# ATmega1284RFR2 register map
Vendor: Atmel; File version: 1.0
CPU: other r0p0, little endian, no MPU, no FPU, 4 interrupt priority bits
Registers are 8-bit, read-write, reset 0x0 unless marked. A register's access mark holds for its fields unless they carry their own. Offsets are from the block's base; [hi:lo] are bit positions; 'fields as' and 'values as' point back to an identical list.

## TC3 — Timer/Counter, 16-bit
Base 0x00800038
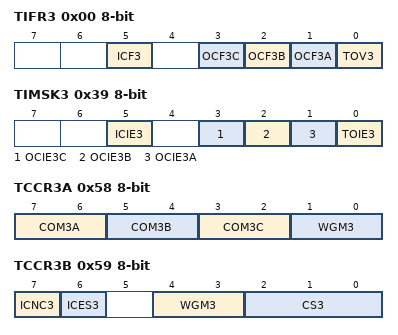
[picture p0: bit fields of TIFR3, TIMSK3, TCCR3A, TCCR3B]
0x00 TIFR3 — Timer/Counter3 Interrupt Flag Register (read-only for debugger)
  [5] ICF3 — Timer/Counter3 Input Capture Flag
  [3] OCF3C — Timer/Counter3 Output Compare C Match Flag
  [2] OCF3B — Timer/Counter3 Output Compare B Match Flag
  [1] OCF3A — Timer/Counter3 Output Compare A Match Flag
  [0] TOV3 — Timer/Counter3 Overflow Flag
0x39 TIMSK3 — Timer/Counter3 Interrupt Mask Register
  [5] ICIE3 — Timer/Counter3 Input Capture Interrupt Enable
  [3] OCIE3C — Timer/Counter3 Output Compare C Match Interrupt Enable
  [2] OCIE3B — Timer/Counter3 Output Compare B Match Interrupt Enable
  [1] OCIE3A — Timer/Counter3 Output Compare A Match Interrupt Enable
  [0] TOIE3 — Timer/Counter3 Overflow Interrupt Enable
0x58 TCCR3A — Timer/Counter3 Control Register A
  [7:6] COM3A — Compare Output Mode for Channel A
    0=NORMAL_PORT_OPERATION_OCNA_OCNB_OCNC_DISCONNECTED; 1=TOGGLE_OCNA_OCNB_OCNC_ON_COMPARE_MATCH; 2=CLEAR_OCNA_OCNB_OCNC_ON_COMPARE_MATCH_SET_OUTPUT_TO_LOW_LEVEL; 3=SET_OCNA_OCNB_OCNC_ON_COMPARE_MATCH_SET_OUTPUT_TO_HIGH_LEVEL
  [5:4] COM3B — Compare Output Mode for Channel B
    values as COM3A
  [3:2] COM3C — Compare Output Mode for Channel C
    values as COM3A
  [1:0] WGM3 — Waveform Generation Mode
    0=NORMAL_MODE_OF_OPERATION; 1=PWM_PHASE_CORRECT_8_BIT; 2=PWM_PHASE_CORRECT_9_BIT; 3=PWM_PHASE_CORRECT_10_BIT
0x59 TCCR3B — Timer/Counter3 Control Register B
  [7] ICNC3 — Input Capture 3 Noise Canceller
  [6] ICES3 — Input Capture 3 Edge Select
  [4:3] WGM3 — Waveform Generation Mode
    values as TCCR3A.WGM3
  [2:0] CS3 — Clock Select
    0=NO_CLOCK_SOURCE_TIMER_COUNTER_STOPPED; 1=CLK_IO_1_NO_PRESCALING; 2=CLK_IO_8_FROM_PRESCALER; 3=CLK_IO_64_FROM_PRESCALER; 4=CLK_IO_256_FROM_PRESCALER; 5=CLK_IO_1024_FROM_PRESCALER; 6=EXTERNAL_CLOCK_SOURCE_ON_TN_PIN_CLOCK_ON_FALLING_EDGE; 7=EXTERNAL_CLOCK_SOURCE_ON_TN_PIN_CLOCK_ON_RISING_EDGE
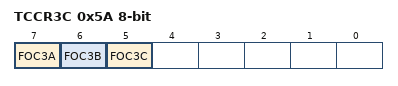
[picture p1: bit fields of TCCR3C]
0x5A TCCR3C — Timer/Counter3 Control Register C
  [7] FOC3A — Force Output Compare for Channel A
  [6] FOC3B — Force Output Compare for Channel B
  [5] FOC3C — Force Output Compare for Channel C
0x5C TCNT3 16-bit (reset mask 0xFF) — Timer/Counter3 Bytes
0x5E ICR3 16-bit (reset mask 0xFF) — Timer/Counter3 Input Capture Register Bytes
0x60 OCR3A 16-bit (reset mask 0xFF) — Timer/Counter3 Output Compare Register A Bytes
0x62 OCR3B 16-bit (reset mask 0xFF) — Timer/Counter3 Output Compare Register B Bytes
0x64 OCR3C 16-bit (reset mask 0xFF) — Timer/Counter3 Output Compare Register C Bytes

## TC4 — Timer/Counter, 16-bit
Base 0x00800039
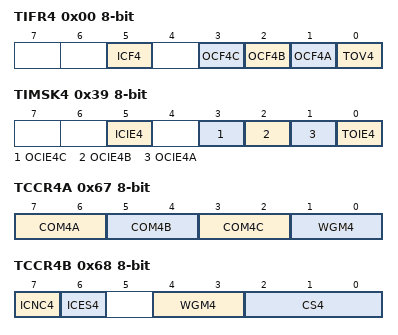
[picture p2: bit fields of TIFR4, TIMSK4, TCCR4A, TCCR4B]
0x00 TIFR4 — Timer/Counter4 Interrupt Flag Register (write-only for debugger)
  [5] ICF4 — Timer/Counter4 Input Capture Flag
  [3] OCF4C — Timer/Counter4 Output Compare C Match Flag
  [2] OCF4B — Timer/Counter4 Output Compare B Match Flag
  [1] OCF4A — Timer/Counter4 Output Compare A Match Flag
  [0] TOV4 — Timer/Counter4 Overflow Flag
0x39 TIMSK4 — Timer/Counter4 Interrupt Mask Register
  [5] ICIE4 — Timer/Counter4 Input Capture Interrupt Enable
  [3] OCIE4C — Timer/Counter4 Output Compare C Match Interrupt Enable
  [2] OCIE4B — Timer/Counter4 Output Compare B Match Interrupt Enable
  [1] OCIE4A — Timer/Counter4 Output Compare A Match Interrupt Enable
  [0] TOIE4 — Timer/Counter4 Overflow Interrupt Enable
0x67 TCCR4A — Timer/Counter4 Control Register A
  [7:6] COM4A — Compare Output Mode for Channel A
    0=NORMAL_OPERATION
  [5:4] COM4B — Compare Output Mode for Channel B
    0=NORMAL_OPERATION
  [3:2] COM4C — Compare Output Mode for Channel C
    0=NORMAL_OPERATION
  [1:0] WGM4 — Waveform Generation Mode
    0=NORMAL_MODE_OF_OPERATION; 1=PWM_PHASE_CORRECT_8_BIT; 2=PWM_PHASE_CORRECT_9_BIT; 3=PWM_PHASE_CORRECT_10_BIT
0x68 TCCR4B — Timer/Counter4 Control Register B
  [7] ICNC4 — Input Capture 4 Noise Canceller
  [6] ICES4 — Input Capture 4 Edge Select
  [4:3] WGM4 — Waveform Generation Mode
    values as TCCR4A.WGM4
  [2:0] CS4 — Clock Select
    0=NO_CLOCK_SOURCE_TIMER_COUNTER_STOPPED; 1=CLK_IO_1_NO_PRESCALING; 2=CLK_IO_8_FROM_PRESCALER; 3=CLK_IO_64_FROM_PRESCALER; 4=CLK_IO_256_FROM_PRESCALER; 5=CLK_IO_1024_FROM_PRESCALER
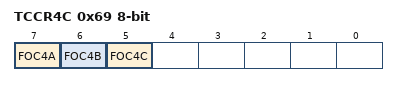
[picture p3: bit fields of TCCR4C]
0x69 TCCR4C — Timer/Counter4 Control Register C
  [7] FOC4A — Force Output Compare for Channel A
  [6] FOC4B — Force Output Compare for Channel B
  [5] FOC4C — Force Output Compare for Channel C
0x6B TCNT4 16-bit (reset mask 0xFF) — Timer/Counter4 Bytes
0x6D ICR4 16-bit (reset mask 0xFF) — Timer/Counter4 Input Capture Register Bytes
0x6F OCR4A 16-bit (reset mask 0xFF) — Timer/Counter4 Output Compare Register A Bytes
0x71 OCR4B 16-bit (reset mask 0xFF) — Timer/Counter4 Output Compare Register B Bytes
0x73 OCR4C 16-bit (reset mask 0xFF) — Timer/Counter4 Output Compare Register C Bytes
